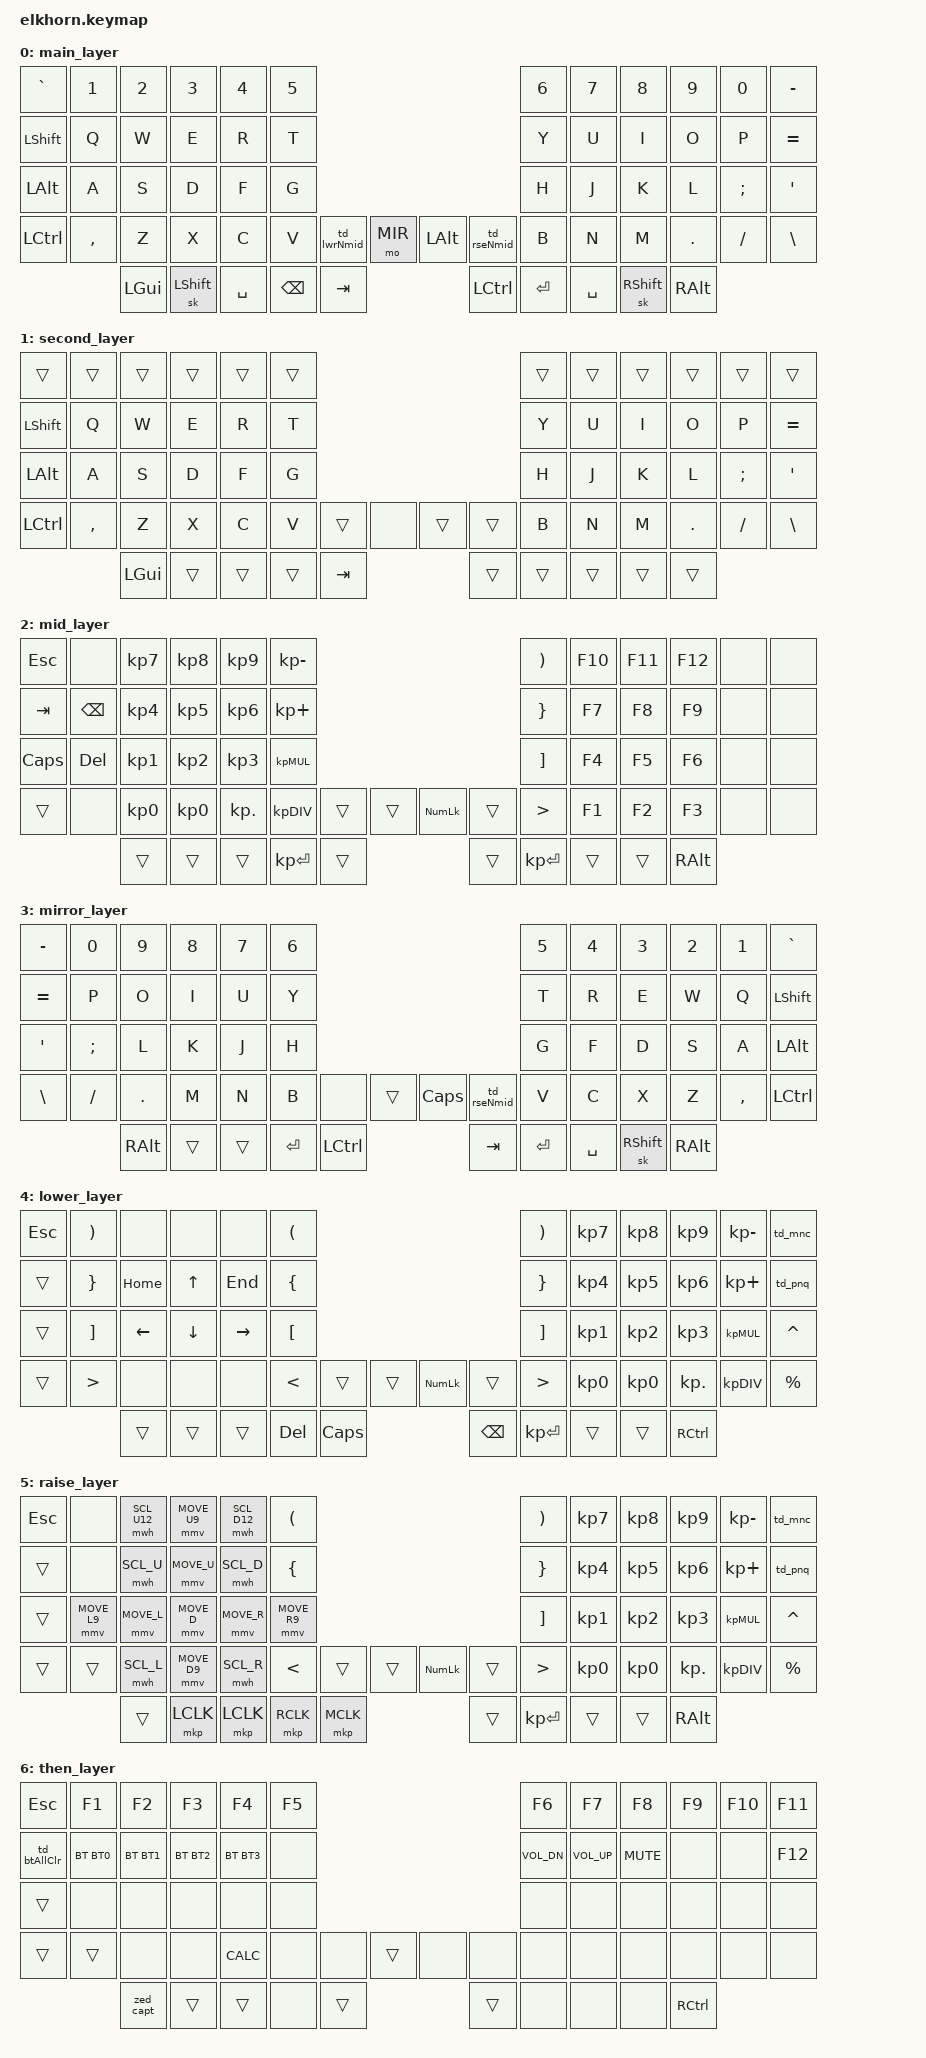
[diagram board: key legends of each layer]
/*
 * Copyright (c) 2020 The ZMK Contributors
 *
 * SPDX-License-Identifier: MIT
 */

#include <behaviors.dtsi>
#include <dt-bindings/zmk/keys.h>
#include <dt-bindings/zmk/outputs.h>
#include <dt-bindings/zmk/bt.h>
#include <dt-bindings/zmk/mouse.h>

#define AS(keycode) &as LS(keycode) keycode     // Autoshift Macro

#define CMK 0
#define QWT 1
#define MID 2
#define MIR 3
#define LWR 4
#define RSE 5
#define THN 6
#define TRS 7


#define SH LSHFT 
#define KP_MUL KP_MULTIPLY
#define KP_DIV KP_DIVIDE
#define LSP SPACE
#define RSP SPACE
#define CL CAPS
#define P0 KP_N0
#define P1 KP_N1
#define P2 KP_N2
#define P3 KP_N3
#define P4 KP_N4
#define P5 KP_N5
#define P6 KP_N6
#define P7 KP_N7
#define P8 KP_N8
#define P9 KP_N9

#define VOL_DN C_VOL_DN
#define VOL_UP C_VOL_UP
#define CALC C_AL_CALC

#define BT0 BT_SEL 0
#define BT1 BT_SEL 1
#define BT2 BT_SEL 2
#define BT3 BT_SEL 3
#define BT4 BT_SEL 4

#define MOVE_U MOVE_VERT(-200)
#define MOVE_D MOVE_VERT(200)
#define MOVE_L MOVE_HOR(-200)
#define MOVE_R MOVE_HOR(200)
#define MOVE_U9 MOVE_VERT(-900)
#define MOVE_D9 MOVE_VERT(900)
#define MOVE_L9 MOVE_HOR(-900)
#define MOVE_R9 MOVE_HOR(900)
#define SCL_U SCROLL_VERT(10)
#define SCL_D SCROLL_VERT(-10)
#define SCL_L SCROLL_HOR(-10)
#define SCL_R SCROLL_HOR(10)
#define SCL_U12 SCROLL_VERT(18)
#define SCL_D12 SCROLL_VERT(-18)
#define SCL_L12 SCROLL_HOR(-18)
#define SCL_R12 SCROLL_HOR(18)


&mmv {
    time-to-max-speed-ms = <0>;
    acceleration-exponent=<0>;
};

&mwh {
    time-to-max-speed-ms = <0>;
    acceleration-exponent=<0>;
};
&mt {
    tapping-term-ms = <100>;
}; 

&sk {
    release-after-ms = <100>;
    quick-release;
}; 

/ {
    behaviors {
        td_lwrNmid: tap_dance_lwrNmid {
            compatible = "zmk,behavior-tap-dance";
            label = "TAP_DANCE_LWR_AND_MID";
            #binding-cells = <0>;
            tapping-term-ms = <280>;
            bindings = <&mo LWR>, <&mo MID>, <&mo MIR>;
        };
        td_rseNmid: tap_dance_rseNmid {
            compatible = "zmk,behavior-tap-dance";
            label = "TAP_DANCE_RSE_AND_MID";
            #binding-cells = <0>;
            tapping-term-ms = <250>;
            bindings = <&mo RSE>, <&mo MID>;
        };
        td_par: tap_dance_par {
            compatible = "zmk,behavior-tap-dance";
            label = "TAP_DANCE_PAR";
            #binding-cells = <0>;
            tapping-term-ms = <200>;
            bindings = <&kp LPAR>, <&kp RPAR>;
        };
        td_pnq: tap_dance_plus_equal {
            compatible = "zmk,behavior-tap-dance";
            label = "TAP_DANCE_PLUS_EQUAL";
            #binding-cells = <0>;
            tapping-term-ms = <220>;
            bindings = <&kp KP_PLUS>, <&kp EQUAL>;
        };
        td_mnc: tap_dance_minus_clear {
            compatible = "zmk,behavior-tap-dance";
            label = "TAP_DANCE_MINUS_CLEAR";
            #binding-cells = <0>;
            tapping-term-ms = <220>;
            bindings = <&kp KP_MINUS>, <&kp ESC>;
        };
        
        td_btAllClr: tap_dance_btAllClr  {
            compatible = "zmk,behavior-tap-dance";
            label = "tap_dance_btAllClr";
            #binding-cells = <0>;
            tapping-term-ms = <200>;
            bindings = <&bt BT_CLR>, <&zed_btAllClr>;
        };
        td_mvu: tap_dance_mvu{
            compatible = "zmk,behavior-tap-dance";
            label = "TAP_DANCE_MVU";
            #binding-cells = <0>;
            tapping-term-ms = <100>;
            bindings = <&mmv MOVE_U>,  <&mmv MOVE_VERT(-7000)>;
        };
        td_mvd: tap_dance_mvd{
            compatible = "zmk,behavior-tap-dance";
            label = "TAP_DANCE_MVD";
            #binding-cells = <0>;
            tapping-term-ms = <100>;
            bindings = <&mmv MOVE_D>,  <&mmv MOVE_VERT(7000)>;
        };
        td_mvl: tap_dance_mvl{
            compatible = "zmk,behavior-tap-dance";
            label = "TAP_DANCE_MVL";
            #binding-cells = <0>;
            tapping-term-ms = <100>;
            bindings = <&mmv MOVE_L>,  <&mmv MOVE_HOR(-7000)>;
        };
        td_mvr: tap_dance_mvr{
            compatible = "zmk,behavior-tap-dance";
            label = "TAP_DANCE_MVR";
            #binding-cells = <0>;
            tapping-term-ms = <100>;
            bindings = <&mmv MOVE_R>,  <&mmv MOVE_HOR(7000)>;
        };
        td_mhu: tap_dance_mhu{
            compatible = "zmk,behavior-tap-dance";
            label = "TAP_DANCE_MHU";
            #binding-cells = <0>;
            tapping-term-ms = <100>;
            bindings = <&mwh SCL_U>,  <&mwh SCL_U12>;
        };
        td_mhd: tap_dance_mhd{
            compatible = "zmk,behavior-tap-dance";
            label = "TAP_DANCE_MHD";
            #binding-cells = <0>;
            tapping-term-ms = <100>;
            bindings = <&mwh SCL_D>,  <&mwh SCL_D12>;
        };
        td_mhl: tap_dance_mhl{
            compatible = "zmk,behavior-tap-dance";
            label = "TAP_DANCE_MHL";
            #binding-cells = <0>;
            tapping-term-ms = <100>;
            bindings = <&mwh SCL_L>,  <&mwh SCL_L12>;
        };
        td_mhr: tap_dance_mhr{
            compatible = "zmk,behavior-tap-dance";
            label = "TAP_DANCE_MHR";
            #binding-cells = <0>;
            tapping-term-ms = <100>;
            bindings = <&mwh SCL_R>,  <&mwh SCL_R12>;
        };

        ht_6: behavior_ht_6{
            compatible = "zmk,behavior-hold-tap";
            label = "ht_6";
            #binding-cells = <2>;
            flavor = "tap-preferred";
            tapping-term-ms = <600>;
            bindings = <&kp>, <&kp>;
        };
    };
    
    conditional_layers {
        compatible = "zmk,conditional-layers";
        tri_layer {
            if-layers = <4 5>;
            then-layer = <6>;
        };
    };


    
    keymap {
        compatible = "zmk,keymap";

        main_layer { //0
            bindings = <
   &kp GRAVE  &kp N1    &kp N2    &kp N3    &kp N4    &kp N5                                                          &kp N6     &kp N7     &kp N8     &kp N9    &kp N0    &kp MINUS
   &kp LSHFT  &kp Q     &kp W     &kp E     &kp R     &kp T                                                           &kp Y      &kp U      &kp I      &kp O     &kp P     &kp EQUAL
   &kp LALT   &kp A     &kp S     &kp D     &kp F     &kp G                                                           &kp H      &kp J      &kp K      &kp L     &kp SEMI  &kp SQT
   &kp LCTRL  &kp COMMA &kp Z     &kp X     &kp C     &kp V     &td_lwrNmid &mo MIR            &kp LALT  &td_rseNmid  &kp B      &kp N      &kp M      &kp DOT   &kp FSLH  &kp BSLH
                        &kp LGUI  &sk LSHFT &kp SPACE &kp BSPC  &kp TAB                                    &kp LCTRL   &kp RET   &kp SPACE   &sk RSHFT  &kp RALT
            >;
        };

        second_layer { //1 qwerty
            bindings = <
   &trans         &trans    &trans    &trans    &trans    &trans                                                     &trans    &trans    &trans    &trans    &trans      &trans
   &kp LSHIFT &kp Q     &kp W     &kp E     &kp R     &kp T                                                          &kp Y     &kp U     &kp I     &kp O     &kp P       &kp EQUAL
   &kp LALT   &kp A     &kp S     &kp D     &kp F     &kp G                                                          &kp H     &kp J     &kp K     &kp L     &kp SEMI    &kp SQT
   &kp LCTRL  &kp COMMA &kp Z     &kp X     &kp C     &kp V     &trans   &none                &trans      &trans     &kp B     &kp N     &kp M     &kp DOT   &kp FSLH    &kp BSLH   
                            &kp LGUI  &trans    &trans    &trans    &kp TAB                        &trans      &trans      &trans      &trans      &trans
            >;
        };
        
        mid_layer { //2
            bindings = <
   &kp ESC   &none     &kp KP_N7  &kp KP_N8  &kp KP_N9  &kp KP_MINUS                                                 &kp RPAR     &kp F10    &kp F11   &kp F12  &none      &none      
   &kp TAB   &kp BSPC  &kp KP_N4  &kp KP_N5  &kp KP_N6  &kp KP_PLUS                                                  &kp RBRC     &kp F7     &kp F8    &kp F9   &none      &none      
   &kp CAPS  &kp DEL   &kp KP_N1  &kp KP_N2  &kp KP_N3  &kp KP_MUL                                                   &kp RBKT     &kp F4     &kp F5    &kp F6   &none      &none      
   &trans    &none     &kp KP_N0  &kp KP_N0  &kp KP_DOT &kp KP_DIV     &trans     &trans        &kp KP_NUM  &trans   &kp GT       &kp F1     &kp F2    &kp F3   &none      &none       
                             &trans       &trans       &trans     &kp KP_ENTER &trans                 &trans      &kp KP_ENTER   &trans      &trans    &kp RALT
            >;
        };
        
        mirror_layer { //3
            bindings = <
   &kp MINUS  &kp N0    &kp N9    &kp N8    &kp N7    &kp N6                                                          &kp N5     &kp N4     &kp N3     &kp N2    &kp N1    &kp GRAVE
   &kp EQUAL  &kp P     &kp O     &kp I     &kp U     &kp Y                                                           &kp T      &kp R      &kp E      &kp W     &kp Q     &kp LSHFT
   &kp SQT    &kp SEMI  &kp L     &kp K     &kp J     &kp H                                                           &kp G      &kp F      &kp D      &kp S     &kp A     &kp LALT
   &kp BSLH   &kp FSLH  &kp DOT   &kp M     &kp N     &kp B     &none       &trans             &kp CAPS  &td_rseNmid  &kp V      &kp C      &kp X      &kp Z     &kp COMMA &kp LCTRL   
                        &kp RALT  &trans    &trans    &kp RET   &kp LCTRL                                   &kp TAB   &kp RET   &kp SPACE   &sk RSHFT  &kp RALT
            >;
        };

        lower_layer { //4
            bindings = <
   &kp ESC   &kp RPAR     &none        &none        &none      &kp LPAR                                                &kp RPAR     &kp KP_N7    &kp KP_N8  &kp KP_N9  &kp KP_MINUS &td_mnc
   &trans    &kp RBRC     &kp HOME     &kp UP       &kp END    &kp LBRC                                                &kp RBRC     &kp KP_N4    &kp KP_N5  &kp KP_N6  &kp KP_PLUS  &td_pnq
   &trans    &kp RBKT     &kp LEFT     &kp DOWN     &kp RIGHT  &kp LBKT                                                &kp RBKT     &kp KP_N1    &kp KP_N2  &kp KP_N3  &kp KP_MUL   &kp CARET
   &trans    &kp GT       &none        &none        &none      &kp LT    &trans     &trans        &kp KP_NUM &trans    &kp GT       &kp KP_N0    &kp KP_N0  &kp KP_DOT &kp KP_DIV   &kp PRCNT  
                              &trans       &trans       &trans     &kp DEL   &kp CAPS                 &kp BSPC  &kp KP_ENTER &trans     &trans      &kp RCTRL
            >;
        };

        raise_layer { //5
                bindings = <
   &kp ESC   &none         &mwh SCL_U12  &mmv MOVE_U9 &mwh SCL_D12 &kp LPAR                                                &kp RPAR     &kp KP_N7    &kp KP_N8 &kp KP_N9  &kp KP_MINUS &td_mnc
   &trans    &none         &mwh SCL_U    &mmv MOVE_U  &mwh SCL_D   &kp LBRC                                                &kp RBRC     &kp KP_N4    &kp KP_N5 &kp KP_N6  &kp KP_PLUS  &td_pnq
   &trans    &mmv MOVE_L9  &mmv MOVE_L   &mmv MOVE_D  &mmv MOVE_R  &mmv MOVE_R9                                            &kp RBKT     &kp KP_N1    &kp KP_N2 &kp KP_N3  &kp KP_MUL   &kp CARET
   &trans    &trans        &mwh SCL_L   &mmv MOVE_D9   &mwh SCL_R  &kp LT    &trans     &trans        &kp KP_NUM &trans    &kp GT       &kp KP_N0    &kp KP_N0 &kp KP_DOT &kp KP_DIV   &kp PRCNT  
                           &trans     &mkp LCLK   &mkp LCLK   &mkp RCLK  &mkp MCLK                               &trans    &kp KP_ENTER &trans       &trans    &kp RALT
            >;
        };

        
        then_layer { //6
            bindings = <
   &kp ESC      &kp F1       &kp F2       &kp F3       &kp F4       &kp F5                                                         &kp F6     &kp F7     &kp F8     &kp F9    &kp F10   &kp F11
   &td_btAllClr &bt BT0      &bt BT1      &bt BT2      &bt BT3      &none                                                          &kp VOL_DN &kp VOL_UP &kp C_MUTE &none     &none     &kp F12
   &trans       &none        &none        &none        &none        &none                                                          &none      &none      &none      &none     &none     &none 
   &trans       &trans       &none        &none        &kp CALC     &none     &none     &trans               &none       &none     &none      &none      &none      &none     &none     &none
                               &zed_capt    &trans       &trans       &none     &trans                             &trans    &none      &none      &none      &kp RCTRL  
            >;
        };
    };
    
    macros {
        
        ZMK_MACRO(zed_capt,wait-ms=<30>; tap-ms=<30>; bindings= 
            <&macro_press &kp LSHFT>, <&macro_press &kp LGUI>
            , <&macro_tap &kp S>
            , <&macro_release &kp LSHFT>, <&macro_release &kp LGUI>;)

        ZMK_MACRO(zed_btAllClr, wait-ms=<1>; tap-ms=<1>; bindings=<&bt BT0  &bt BT_CLR &bt BT1  &bt BT_CLR &bt BT2  &bt BT_CLR &bt BT3  &bt BT_CLR>;)
    };
};
